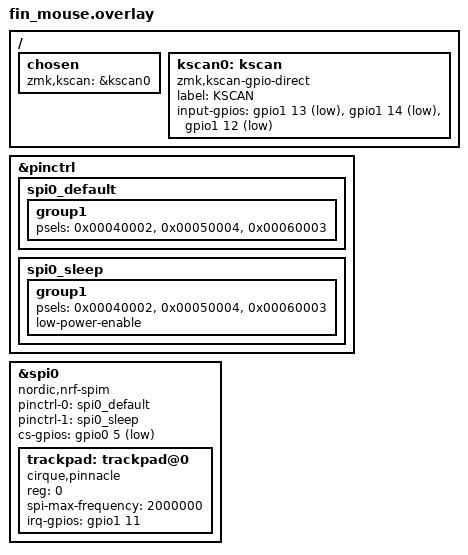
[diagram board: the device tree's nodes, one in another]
#include <dt-bindings/gpio/gpio.h>
#include <dt-bindings/zmk/matrix_transform.h>

/ {
    chosen {
        zmk,kscan = &kscan0;
    };

    kscan0: kscan {
        compatible = "zmk,kscan-gpio-direct";
        label = "KSCAN";
        input-gpios
            = <&gpio1 13 (GPIO_ACTIVE_LOW | GPIO_PULL_UP)>
            , <&gpio1 14 (GPIO_ACTIVE_LOW | GPIO_PULL_UP)>
            , <&gpio1 12 (GPIO_ACTIVE_LOW | GPIO_PULL_UP)>
            ;
    };
};

&pinctrl {
    spi0_default: spi0_default {
        group1 {
            psels = <0x00040002>,
                    <0x00050004>,
                    <0x00060003>;
        };
    };
    spi0_sleep: spi0_sleep {
        group1 {
            psels = <0x00040002>,
                    <0x00050004>,
                    <0x00060003>;
            low-power-enable;
        };
    };
};

&spi0 {
    status = "okay";
    compatible = "nordic,nrf-spim";
    pinctrl-0 = <&spi0_default>;
    pinctrl-1 = <&spi0_sleep>;
    pinctrl-names = "default", "sleep";

    cs-gpios = <&gpio0 5 GPIO_ACTIVE_LOW>;

    trackpad: trackpad@0 {
        compatible = "cirque,pinnacle";
        reg = <0>;
        spi-max-frequency = <2000000>;
        status = "okay";
        irq-gpios = <&gpio1 11 (GPIO_ACTIVE_HIGH | GPIO_PULL_DOWN)>;
    };
};
